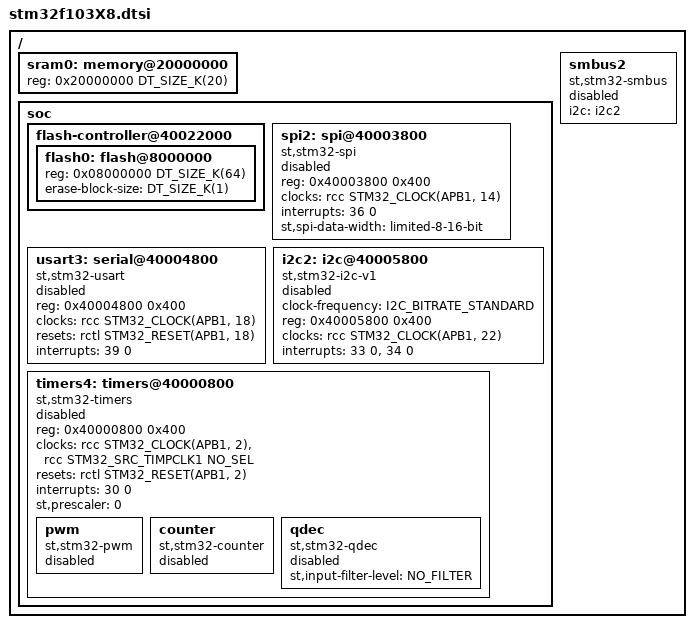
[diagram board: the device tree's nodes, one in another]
/*
 * Copyright (c) 2018 Linaro Limited
 *
 * SPDX-License-Identifier: Apache-2.0
 */

#include <st/f1/stm32f103X6.dtsi>

/ {
	sram0: memory@20000000 {
		reg = <0x20000000 DT_SIZE_K(20)>;
	};

	soc {
		flash-controller@40022000 {
			flash0: flash@8000000 {
				reg = <0x08000000 DT_SIZE_K(64)>;
				ranges = <0 0x8000000 DT_SIZE_K(64)>;
				erase-block-size = <DT_SIZE_K(1)>;
			};
		};

		/* spi2 is present on all STM32F103x8 SoCs except
		 * STM32F103T8. Delete node in stm32f103t8.dtsi.
		 */
		spi2: spi@40003800 {
			compatible = "st,stm32-spi";
			#address-cells = <1>;
			#size-cells = <0>;
			reg = <0x40003800 0x400>;
			clocks = <&rcc STM32_CLOCK(APB1, 14)>;
			interrupts = <36 0>;
			st,spi-data-width = "limited-8-16-bit";
			status = "disabled";
		};

		usart3: serial@40004800 {
			compatible = "st,stm32-usart", "st,stm32-uart";
			reg = <0x40004800 0x400>;
			clocks = <&rcc STM32_CLOCK(APB1, 18)>;
			resets = <&rctl STM32_RESET(APB1, 18)>;
			interrupts = <39 0>;
			status = "disabled";
		};

		i2c2: i2c@40005800 {
			compatible = "st,stm32-i2c-v1";
			clock-frequency = <I2C_BITRATE_STANDARD>;
			#address-cells = <1>;
			#size-cells = <0>;
			reg = <0x40005800 0x400>;
			clocks = <&rcc STM32_CLOCK(APB1, 22)>;
			interrupts = <33 0>, <34 0>;
			interrupt-names = "event", "error";
			status = "disabled";
		};

		timers4: timers@40000800 {
			compatible = "st,stm32-timers";
			reg = <0x40000800 0x400>;
			clocks = <&rcc STM32_CLOCK(APB1, 2)>,
				 <&rcc STM32_SRC_TIMPCLK1 NO_SEL>;
			resets = <&rctl STM32_RESET(APB1, 2)>;
			interrupts = <30 0>;
			interrupt-names = "global";
			st,prescaler = <0>;
			status = "disabled";

			pwm {
				compatible = "st,stm32-pwm";
				status = "disabled";
				#pwm-cells = <3>;
			};

			counter {
				compatible = "st,stm32-counter";
				status = "disabled";
			};

			qdec {
				compatible = "st,stm32-qdec";
				st,input-filter-level = <NO_FILTER>;
				status = "disabled";
			};
		};
	};

	smbus2: smbus2 {
		compatible = "st,stm32-smbus";
		#address-cells = <1>;
		#size-cells = <0>;
		i2c = <&i2c2>;
		status = "disabled";
	};
};
